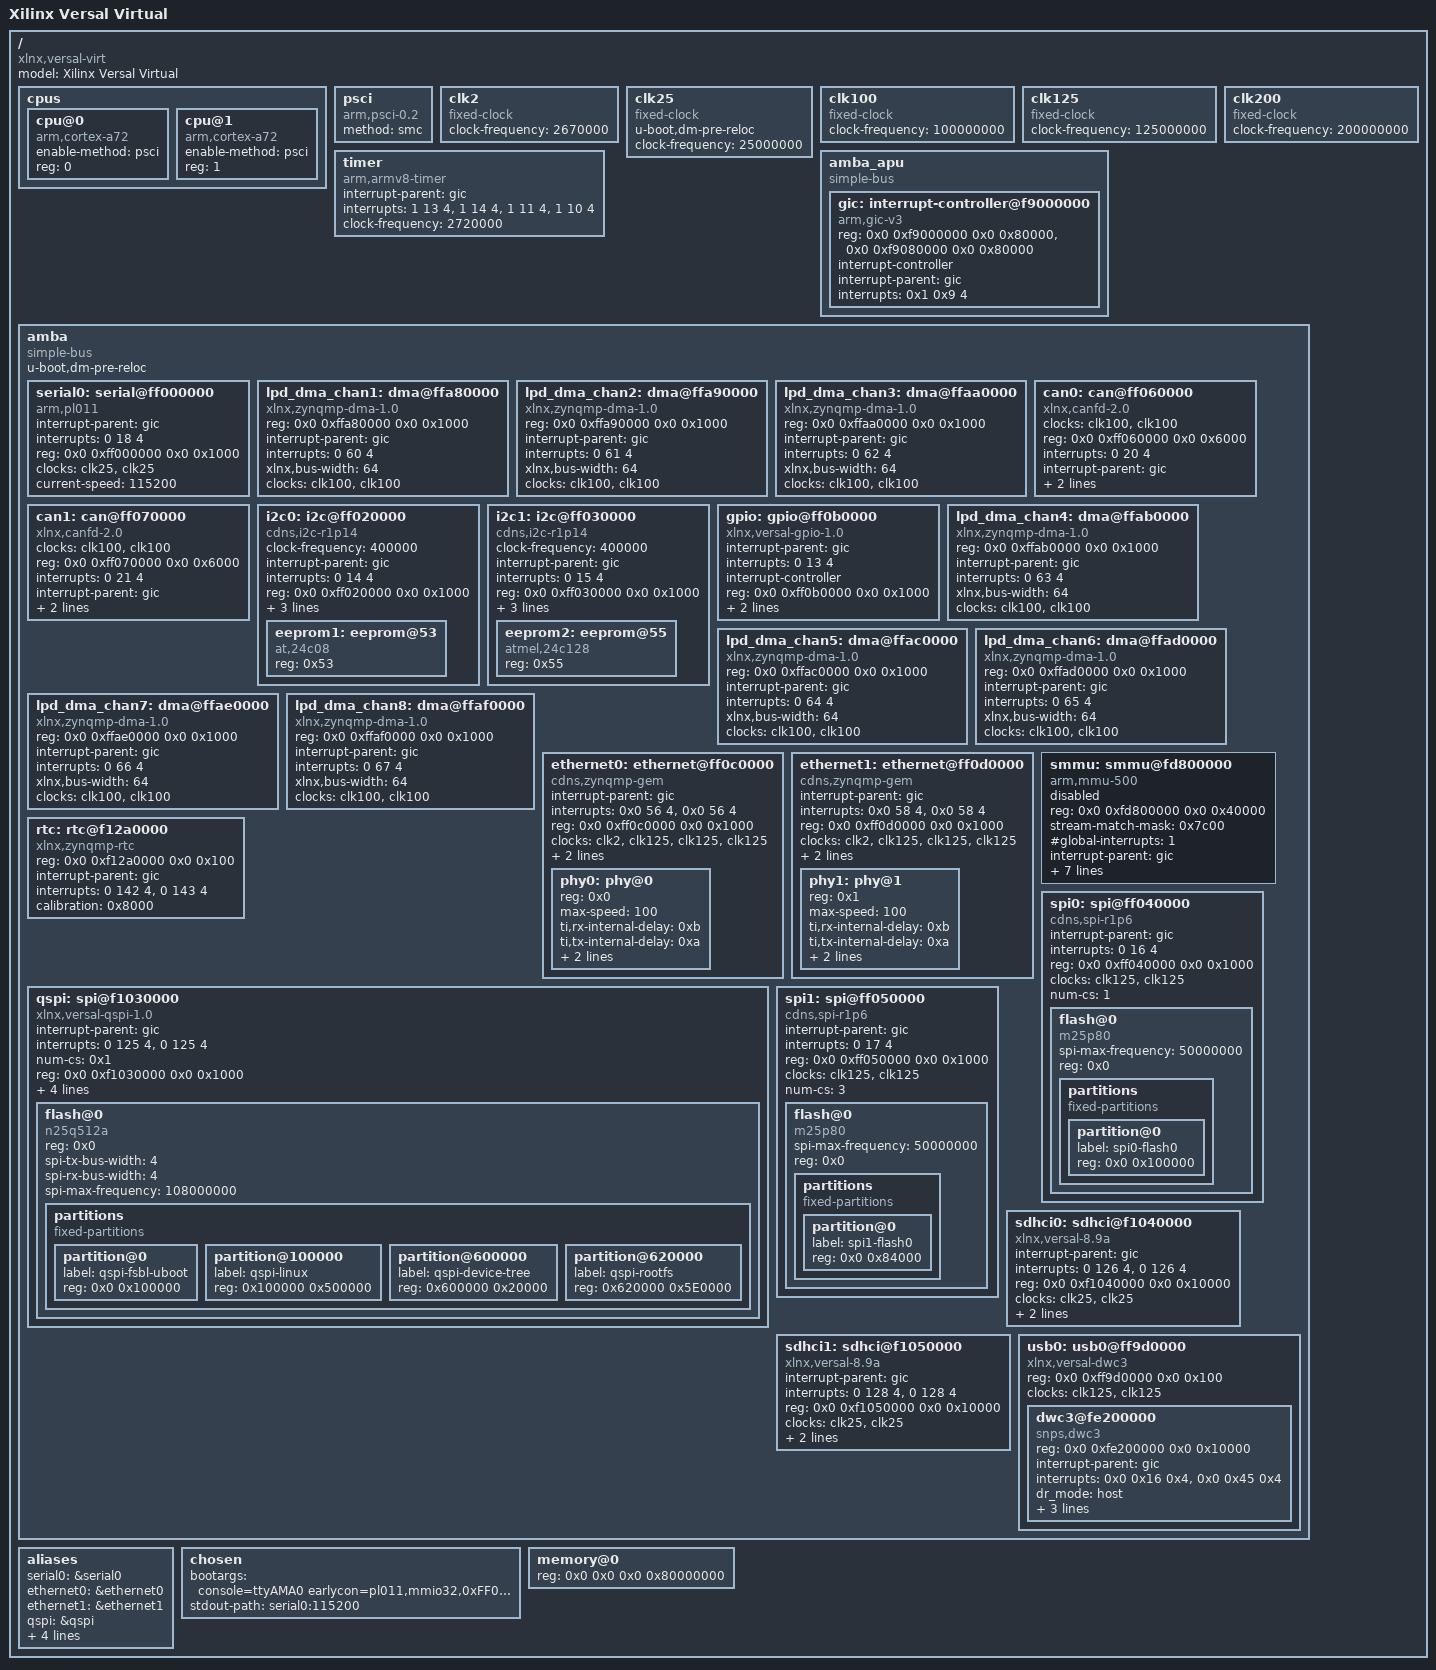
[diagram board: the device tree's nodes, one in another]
#include "include/dt-bindings/gpio/gpio.h"

/ {
	compatible = "xlnx,versal-virt", "xlnx,versal";
	#address-cells = <2>;
	#size-cells = <2>;
	model = "Xilinx Versal Virtual";

	cpus {
		#address-cells = <1>;
		#size-cells = <0>;

		cpu@0 {
			compatible = "arm,cortex-a72", "arm,armv8";
			device_type = "cpu";
			enable-method = "psci";
			reg = <0>;
		};
		cpu@1 {
			compatible = "arm,cortex-a72", "arm,armv8";
			device_type = "cpu";
			enable-method = "psci";
			reg = <1>;
		};
	};

	psci {
		compatible = "arm,psci-0.2";
		method = "smc";
	};

	clk2: clk2 {
		compatible = "fixed-clock";
		#clock-cells = <0x0>;
		clock-frequency = <2670000>;
	};

	clk25: clk25 {
		u-boot,dm-pre-reloc;
		compatible = "fixed-clock";
		#clock-cells = <0x0>;
		clock-frequency = <25000000>;
	};

	clk100: clk100 {
		compatible = "fixed-clock";
		#clock-cells = <0x0>;
		clock-frequency = <100000000>;
	};

	clk125: clk125 {
		compatible = "fixed-clock";
		#clock-cells = <0x0>;
		clock-frequency = <125000000>;
	};

	clk200: clk200 {
		compatible = "fixed-clock";
		#clock-cells = <0>;
		clock-frequency = <200000000>;
	};

	timer {
		compatible = "arm,armv8-timer";
		interrupt-parent = <&gic>;
		interrupts = <1 13 4>,
			     <1 14 4>,
			     <1 11 4>,
			     <1 10 4>;
		clock-frequency = <2720000>;
	};

	amba_apu: amba_apu {
		compatible = "simple-bus";
		#address-cells = <2>;
		#size-cells = <2>;
		ranges;

		gic: interrupt-controller@f9000000 {
			compatible = "arm,gic-v3";
			#interrupt-cells = <3>;
			reg = <0x0 0xf9000000 0x0 0x80000>, /* GICD */
			      <0x0 0xf9080000 0x0 0x80000>; /* GICR */
			interrupt-controller;
			interrupt-parent = <&gic>;
			interrupts = <0x1 0x9 4>;
		};
	};

	amba: amba {
		u-boot,dm-pre-reloc;
		compatible = "simple-bus";
		#address-cells = <0x2>;
		#size-cells = <0x2>;
		ranges;

		serial0: serial@ff000000 {
			compatible = "arm,pl011", "arm,sbsa-uart";
			status = "okay";
			interrupt-parent = <&gic>;
			interrupts = <0 18 4>;
			reg = <0x0 0xff000000 0x0 0x1000>;
			clock-names = "uart_clk", "apb_clk";
			clocks = <&clk25 &clk25>;
			current-speed = <115200>;
		};

		lpd_dma_chan1: dma@ffa80000 {
			status = "okay";
			compatible = "xlnx,zynqmp-dma-1.0";
			clock-names = "clk_main", "clk_apb";
			reg = <0x0 0xffa80000 0x0 0x1000>;
			interrupt-parent = <&gic>;
			interrupts = <0 60 4>;
			/* iommus = <&smmu 0x210>; */
			xlnx,bus-width = <64>;
			clocks = <&clk100 &clk100>;
		};

		lpd_dma_chan2: dma@ffa90000 {
			status = "okay";
			compatible = "xlnx,zynqmp-dma-1.0";
			clock-names = "clk_main", "clk_apb";
			reg = <0x0 0xffa90000 0x0 0x1000>;
			interrupt-parent = <&gic>;
			interrupts = <0 61 4>;
			/* iommus = <&smmu 0x212>; */
			xlnx,bus-width = <64>;
			clocks = <&clk100 &clk100>;
		};

		lpd_dma_chan3: dma@ffaa0000 {
			status = "okay";
			compatible = "xlnx,zynqmp-dma-1.0";
			clock-names = "clk_main", "clk_apb";
			reg = <0x0 0xffaa0000 0x0 0x1000>;
			interrupt-parent = <&gic>;
			interrupts = <0 62 4>;
			/* iommus = <&smmu 0x214>; */
			xlnx,bus-width = <64>;
			clocks = <&clk100 &clk100>;
		};

		can0: can@ff060000 {
			compatible = "xlnx,canfd-2.0";
			status = "okay";
			clock-names = "can_clk", "s_axi_aclk";
			clocks = <&clk100 &clk100>;
			reg = <0x0 0xff060000 0x0 0x6000>;
			interrupts = <0 20 4>;
			interrupt-parent = <&gic>;
			tx-fifo-depth = <0x20>;
			rx-fifo-depth = <0x40>;
		};

		can1: can@ff070000 {
			compatible = "xlnx,canfd-2.0";
			status = "okay";
			clock-names = "can_clk", "s_axi_aclk";
			clocks = <&clk100 &clk100>;
			reg = <0x0 0xff070000 0x0 0x6000>;
			interrupts = <0 21 4>;
			interrupt-parent = <&gic>;
			tx-fifo-depth = <0x20>;
			rx-fifo-depth = <0x40>;
		};

		i2c0: i2c@ff020000 {
			compatible = "cdns,i2c-r1p14", "cdns,i2c-r1p10";
			status = "okay";
			clock-frequency = <400000>;
			interrupt-parent = <&gic>;
			interrupts = <0 14 4>;
			reg = <0x0 0xff020000 0x0 0x1000>;
			scl-gpios = <&gpio 14 GPIO_ACTIVE_HIGH>;
			sda-gpios = <&gpio 15 GPIO_ACTIVE_HIGH>;
			#address-cells = <1>;
			#size-cells = <0>;
			clocks = <&clk25>;
			eeprom1: eeprom@53 {
				reg = <0x53>;
				compatible = "at,24c08";
			};
		};

		i2c1: i2c@ff030000 {
			compatible = "cdns,i2c-r1p14", "cdns,i2c-r1p10";
			status = "okay";
			clock-frequency = <400000>;
			interrupt-parent = <&gic>;
			interrupts = <0 15 4>;
			reg = <0x0 0xff030000 0x0 0x1000>;
			scl-gpios = <&gpio 16 GPIO_ACTIVE_HIGH>;
			sda-gpios = <&gpio 17 GPIO_ACTIVE_HIGH>;
			#address-cells = <1>;
			#size-cells = <0>;
			clocks = <&clk25>;
			eeprom2: eeprom@55 {
				compatible = "atmel,24c128";
				reg = <0x55>;
			};
		};

		gpio: gpio@ff0b0000 {
			compatible = "xlnx,versal-gpio-1.0";
			status = "okay";
			#gpio-cells = <0x2>;
			interrupt-parent = <&gic>;
			interrupts = <0 13 4>;
			interrupt-controller;
			#interrupt-cells = <2>;
			reg = <0x0 0xff0b0000 0x0 0x1000>;
			gpio-controller;
			clocks = <&clk25>;
		};


		lpd_dma_chan4: dma@ffab0000 {
			status = "okay";
			compatible = "xlnx,zynqmp-dma-1.0";
			clock-names = "clk_main", "clk_apb";
			reg = <0x0 0xffab0000 0x0 0x1000>;
			interrupt-parent = <&gic>;
			interrupts = <0 63 4>;
			/* iommus = <&smmu 0x216>; */
			xlnx,bus-width = <64>;
			clocks = <&clk100 &clk100>;
		};

		lpd_dma_chan5: dma@ffac0000 {
			status = "okay";
			compatible = "xlnx,zynqmp-dma-1.0";
			clock-names = "clk_main", "clk_apb";
			reg = <0x0 0xffac0000 0x0 0x1000>;
			interrupt-parent = <&gic>;
			interrupts = <0 64 4>;
			/* iommus = <&smmu 0x218>; */
			xlnx,bus-width = <64>;
			clocks = <&clk100 &clk100>;
		};

		lpd_dma_chan6: dma@ffad0000 {
			status = "okay";
			compatible = "xlnx,zynqmp-dma-1.0";
			clock-names = "clk_main", "clk_apb";
			reg = <0x0 0xffad0000 0x0 0x1000>;
			interrupt-parent = <&gic>;
			interrupts = <0 65 4>;
			/* iommus = <&smmu 0x21a>; */
			xlnx,bus-width = <64>;
			clocks = <&clk100 &clk100>;
		};

		lpd_dma_chan7: dma@ffae0000 {
			status = "okay";
			compatible = "xlnx,zynqmp-dma-1.0";
			clock-names = "clk_main", "clk_apb";
			reg = <0x0 0xffae0000 0x0 0x1000>;
			interrupt-parent = <&gic>;
			interrupts = <0 66 4>;
			/* iommus = <&smmu 0x21c>; */
			xlnx,bus-width = <64>;
			clocks = <&clk100 &clk100>;
		};

		lpd_dma_chan8: dma@ffaf0000 {
			status = "okay";
			compatible = "xlnx,zynqmp-dma-1.0";
			clock-names = "clk_main", "clk_apb";
			reg = <0x0 0xffaf0000 0x0 0x1000>;
			interrupt-parent = <&gic>;
			interrupts = <0 67 4>;
			/* iommus = <&smmu 0x21e>; */
			xlnx,bus-width = <64>;
			clocks = <&clk100 &clk100>;
		};

		ethernet0: ethernet@ff0c0000 {
			compatible = "cdns,zynqmp-gem";
			status = "okay";
			interrupt-parent = <&gic>;
			interrupts = <0x0 56 4>, <0x0 56 4>;
			reg = <0x0 0xff0c0000 0x0 0x1000>;
			clock-names = "pclk", "hclk", "tx_clk", "rx_clk";
			clocks = <&clk2 &clk125 &clk125 &clk125>;
			#address-cells = <0x1>;
			#size-cells = <0x0>;
			/* iommus = <&smmu 0x234>; */

			phy-handle = <&phy0>;
			phy-mode = "rgmii-id";

			phy0: phy@0 {
				reg = <0x0>;
				max-speed = <100>;
				ti,rx-internal-delay = <0xb>;
				ti,tx-internal-delay = <0xa>;
				ti,fifo-depth = <0x1>;
				ti,rxctrl-strap-worka;
			};
		};

		ethernet1: ethernet@ff0d0000 {
			compatible = "cdns,zynqmp-gem";
			status = "okay";
			interrupt-parent = <&gic>;
			interrupts = <0x0 58 4>, <0x0 58 4>;
			reg = <0x0 0xff0d0000 0x0 0x1000>;
			clock-names = "pclk", "hclk", "tx_clk", "rx_clk";
			clocks = <&clk2 &clk125 &clk125 &clk125>;
			#address-cells = <0x1>;
			#size-cells = <0x0>;
			/* iommus = <&smmu 0x235>; */

			phy-handle = <&phy1>;
			phy-mode = "rgmii-id";

			phy1: phy@1 {
				reg = <0x1>;
				max-speed = <100>;
				ti,rx-internal-delay = <0xb>;
				ti,tx-internal-delay = <0xa>;
				ti,fifo-depth = <0x1>;
				ti,rxctrl-strap-worka;
			};
		};

		smmu: smmu@fd800000 {
			compatible = "arm,mmu-500";
			reg = <0x0 0xfd800000 0x0 0x40000>;
			stream-match-mask = <0x7c00>;
			#iommu-cells = <1>;
			status = "disabled";
			#global-interrupts = <1>;
			interrupt-parent = <&gic>;
			interrupts = <0 107 4>,
				     <0 107 4>, <0 107 4>, <0 107 4>, <0 107 4>,
				     <0 107 4>, <0 107 4>, <0 107 4>, <0 107 4>,
				     <0 107 4>, <0 107 4>, <0 107 4>, <0 107 4>,
				     <0 107 4>, <0 107 4>, <0 107 4>, <0 107 4>,
				     <0 107 4>, <0 107 4>, <0 107 4>, <0 107 4>,
				     <0 107 4>, <0 107 4>, <0 107 4>, <0 107 4>,
				     <0 107 4>, <0 107 4>, <0 107 4>, <0 107 4>,
				     <0 107 4>, <0 107 4>, <0 107 4>, <0 107 4>;
		};

		rtc: rtc@f12a0000 {
			compatible = "xlnx,zynqmp-rtc";
			status = "okay";
			reg = <0x0 0xf12a0000 0x0 0x100>;
			interrupt-parent = <&gic>;
			interrupts = <0 142 4>, <0 143 4>;
			interrupt-names = "alarm", "sec";
			calibration = <0x8000>;
		};

		qspi: spi@f1030000 {
			compatible = "xlnx,versal-qspi-1.0";
			status = "okay";
			clock-names = "ref_clk", "pclk";
			interrupt-parent = <&gic>;
			interrupts = <0 125 4>, <0 125 4>;
			num-cs = <0x1>;
			reg = <0x0 0xf1030000 0x0 0x1000>;
			#address-cells = <1>;
			#size-cells = <0>;
			/* iommus = <&smmu 0x244>; */
			clocks = <&clk125 &clk125>;
			is-dual = <1>;
			spi-rx-bus-width = <4>;
			spi-tx-bus-width = <4>;

			flash@0 {
				compatible = "n25q512a", "micron,m25p80";
				reg = <0x0>;
				spi-tx-bus-width = <4>;
				spi-rx-bus-width = <4>;
				spi-max-frequency = <108000000>;

				partitions {
					compatible = "fixed-partitions";
					#address-cells = <1>;
					#size-cells = <1>;

					partition@0 {
						label = "qspi-fsbl-uboot";
						reg = <0x0 0x100000>;
					};
					partition@100000 {
						label = "qspi-linux";
						reg = <0x100000 0x500000>;
					};
					partition@600000 {
						label = "qspi-device-tree";
						reg = <0x600000 0x20000>;
					};
					partition@620000 {
						label = "qspi-rootfs";
						reg = <0x620000 0x5E0000>;
					};
				};
			};
		};

		spi0: spi@ff040000 {
			compatible = "cdns,spi-r1p6";
			status = "okay";
			interrupt-parent = <&gic>;
			interrupts = <0 16 4>;
			reg = <0x0 0xff040000 0x0 0x1000>;
			clock-names = "ref_clk", "pclk";
			#address-cells = <1>;
			#size-cells = <0>;
			clocks = <&clk125 &clk125>;
			num-cs = <1>;
			pinctrl-names = "default";

			flash@0 {
				compatible = "m25p80";
				spi-max-frequency = <50000000>;
				reg = <0x0>;

				partitions {
					compatible = "fixed-partitions";
					#address-cells = <1>;
					#size-cells = <1>;

					partition@0 {
						label = "spi0-flash0";
						reg = <0x0 0x100000>;
					};
				};
			};
		};

		spi1: spi@ff050000 {
			compatible = "cdns,spi-r1p6";
			status = "okay";
			interrupt-parent = <&gic>;
			interrupts = <0 17 4>;
			reg = <0x0 0xff050000 0x0 0x1000>;
			clock-names = "ref_clk", "pclk";
			#address-cells = <1>;
			#size-cells = <0>;
			clocks = <&clk125 &clk125>;
			num-cs = <3>;

			flash@0 {
				compatible = "m25p80";
				spi-max-frequency = <50000000>;
				reg = <0x0>;

				partitions {
					compatible = "fixed-partitions";
					#address-cells = <1>;
					#size-cells = <1>;

					partition@0 {
						label = "spi1-flash0";
						reg = <0x0 0x84000>;
					};
				};
			};
		};


		sdhci0: sdhci@f1040000 {
			compatible = "xlnx,versal-8.9a", "arasan,sdhci-8.9a";
			status = "okay";
			interrupt-parent = <&gic>;
			interrupts = <0 126 4>, <0 126 4>;
			reg = <0x0 0xf1040000 0x0 0x10000>;
			clock-names = "clk_xin", "clk_ahb";
			clocks = <&clk25 &clk25>;
			xlnx,device_id = <0>;
			xlnx,mio_bank = <0>;
			/* iommus = <&smmu 0x242>; */
		};

		sdhci1: sdhci@f1050000 {
			compatible = "xlnx,versal-8.9a", "arasan,sdhci-8.9a";
			status = "okay";
			interrupt-parent = <&gic>;
			interrupts = <0 128 4>, <0 128 4>;
			reg = <0x0 0xf1050000 0x0 0x10000>;
			clock-names = "clk_xin", "clk_ahb";
			clocks = <&clk25 &clk25>;
			xlnx,device_id = <1>;
			xlnx,mio_bank = <0>;
			/* iommus = <&smmu 0x243>; */
		};

		usb0: usb0@ff9d0000 {
			compatible = "xlnx,versal-dwc3";
			#address-cells = <0x2>;
			#size-cells = <0x2>;
			status = "okay";
			reg = <0x0 0xff9d0000 0x0 0x100>;
			ranges;
			clock-names = "bus_clk", "ref_clk";
			clocks = <&clk125 &clk125>;

			dwc3@fe200000 {
				compatible = "snps,dwc3";
				status = "okay";
				reg = <0x0 0xfe200000 0x0 0x10000>;
				interrupt-parent = <&gic>;
				interrupts = <0x0 0x16 0x4>, <0x0 0x45 0x4>;
				/* iommus = <&smmu 0x230>; */
				dr_mode = "host";
				maximum-speed = "high-speed";
				snps,dis_u2_susphy_quirk;
				snps,dis_u3_susphy_quirk;
			};
		};
	};

	aliases {
		serial0 = &serial0;
		ethernet0 = &ethernet0;
		ethernet1 = &ethernet1;
		qspi = &qspi;
		spi0 = &spi0;
		spi1 = &spi1;
		mmc0 = &sdhci0;
		mmc1 = &sdhci1;
	};

	chosen {
		bootargs = "console=ttyAMA0 earlycon=pl011,mmio32,0xFF000000,115200n8 clk_ignore_unused maxcpus=2";
		stdout-path = "serial0:115200";
	};

	memory@0 {
		device_type = "memory";
		reg = <0x0 0x0 0x0 0x80000000>;
	};
};
